AUTOSAR XML (schema 4-0-3)
package /ComponentTypes
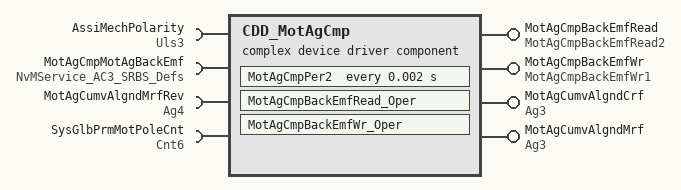
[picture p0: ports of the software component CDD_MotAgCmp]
  complex device driver sw component type CDD_MotAgCmp
    4 x provide port:
      MotAgCmpBackEmfRead: server-com-spec{operation=Oper, queue-length=1}, provided-interface=MotAgCmpBackEmfRead2
      MotAgCmpBackEmfWr: server-com-spec{operation=Oper, queue-length=1}, provided-interface=MotAgCmpBackEmfWr1
      MotAgCumvAlgndCrf: nonqueued-sender-com-spec{data-element=Val, init-value=0}, provided-interface=Ag3
      MotAgCumvAlgndMrf: nonqueued-sender-com-spec{data-element=Val, init-value=0}, provided-interface=Ag3
    4 x require port:
      AssiMechPolarity: nonqueued-receiver-com-spec{data-element=Val, filter=data-filter-type=ALWAYS, init-value=1}, required-interface=Uls3
      MotAgCmpMotAgBackEmf: required-interface=NvMService_AC3_SRBS_Defs
      MotAgCumvAlgndMrfRev: nonqueued-receiver-com-spec{data-element=Val, filter=data-filter-type=ALWAYS, init-value=0}, required-interface=Ag4
      SysGlbPrmMotPoleCnt: parameter-require-com-spec{init-value=6, parameter=Val}, required-interface=Cnt6
    behavior CDD_MotAgCmp_InternalBehavior: data-type-mapping=Nexteer
      ar-typed-per-instance-memorys:
        4 x data, all with sw-calibration-access=READ-ONLY:
          MotAgCmpFirstRunCmpl: type=Logl1
          MotAgCmpMotAgBackEmf: type=Ag9
          MotAgCmpMotCtrlMotAgCumvAlgndMrfRevSVPrev: type=Ag8
          MotAgCmpMotCtrlMotAgMeclPrev: type=Ag8
      operation invoked event OIT_MotAgCmpBackEmfRead_Oper_MotAgCmpBackEmfRead_Oper: start-on-event=MotAgCmpBackEmfRead_Oper, operation=MotAgCmpBackEmfRead.Oper
      operation invoked event OIT_MotAgCmpBackEmfWr_Oper_MotAgCmpBackEmfWr_Oper: start-on-event=MotAgCmpBackEmfWr_Oper, operation=MotAgCmpBackEmfWr.Oper
      timing event TMT_MotAgCmpPer2: start-on-event=MotAgCmpPer2, period=0.002
      runnable MotAgCmpBackEmfRead_Oper
      runnable MotAgCmpBackEmfWr_Oper
        sync call SC_MotAgCmpMotAgBackEmf_SetRamBlockStatus: operation=MotAgCmpMotAgBackEmf.SetRamBlockStatus, timeout=0
      runnable MotAgCmpPer2
        data-receive-point-by-arguments:
          access REC_AssiMechPolarity_Val: accessed-variable=AssiMechPolarity.Val
          access REC_MotAgCumvAlgndMrfRev_Val: accessed-variable=MotAgCumvAlgndMrfRev.Val
        data-send-points:
          access SEND_MotAgCumvAlgndCrf_Val: accessed-variable=MotAgCumvAlgndCrf.Val
          access SEND_MotAgCumvAlgndMrf_Val: accessed-variable=MotAgCumvAlgndMrf.Val
      swc service dependency NvmMotAgCmpMotAgBackEmf
        assigned-datas:
          role=ramBlock, used-data-element=MotAgCmpMotAgBackEmf
          role=defaultValue, used-parameter-element=MotAgCmpMotAgBackEmfDft
        assigned-ports:
          port-prototype=MotAgCmpMotAgBackEmf, role=NvMService_AC3_SRBS_DS
          port-prototype=MotAgCmpMotAgBackEmf, role=NvMService_AC3_SRBS_DS
        service-needs:
          nv block needs NvmMotAgCmpMotAgBackEmf: n-data-sets=0, readonly=false, reliability=ERROR-DETECTION, resistant-to-changed-sw=true, restore-at-start=true, store-at-shutdown=true, write-only-once=false, writing-frequency=0, writing-priority=LOW
      shared-parameters:
        parameter data prototype MotAgCmpMotAgBackEmfDft: sw-calibration-access=READ-WRITE, type=Ag9, init-value=0
  swc implementation CDD_MotAgCmp_Implementation: behavior=CDD_MotAgCmp_InternalBehavior
    code-descriptors:
      code Default: artifact-descriptors=autosar-engineering-object={short-label=Default, category=SWSRC}
